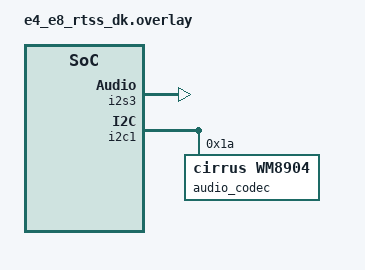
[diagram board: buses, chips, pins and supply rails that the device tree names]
/*
 * Copyright (C) Alif Semiconductor - All Rights Reserved.
 * Use, distribution and modification of this code is permitted under the
 * terms stated in the Alif Semiconductor Software License Agreement
 *
 * You should have received a copy of the Alif Semiconductor Software
 * License Agreement with this file. If not, please write to:
 * contact@alifsemi.com, or visit: https://alifsemi.com/license
 */

/ {
	aliases {
		i2s-codec-tx = &i2s3;
	};
};

&i2s3 {
	status = "okay";
};

&i2c1 {
	status = "okay";

	audio_codec: wm8904@1a {
		compatible = "cirrus,wm8904";
		reg = <0x1a>;
		status = "okay";
	};
};
